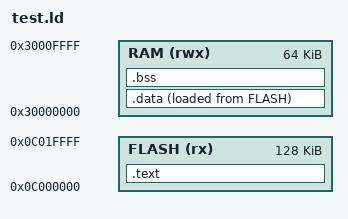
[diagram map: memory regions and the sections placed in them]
/* test.ld
 *
 * Copyright (C) 2026 wolfSSL Inc.
 *
 * This file is part of wolfTrust.
 *
 * wolfTrust is free software; you can redistribute it and/or modify
 * it under the terms of the GNU General Public License as published by
 * the Free Software Foundation; either version 3 of the License, or
 * (at your option) any later version.
 *
 * wolfTrust is distributed in the hope that it will be useful,
 * but WITHOUT ANY WARRANTY; without even the implied warranty of
 * MERCHANTABILITY or FITNESS FOR A PARTICULAR PURPOSE.  See the
 * GNU General Public License for more details.
 *
 * You should have received a copy of the GNU General Public License
 * along with this program; if not, see <https://www.gnu.org/licenses/>.
 */

ENTRY(Reset_Handler)
MEMORY
{
    FLASH (rx) : ORIGIN = 0x0C000000, LENGTH = 128K
    RAM (rwx) : ORIGIN = 0x30000000, LENGTH = 64K
}
_estack = ORIGIN(RAM) + LENGTH(RAM);
SECTIONS
{
    .text : {
        KEEP(*(.vectors))
        *(.text*)
        *(.rodata*)
    } > FLASH
    .data : { *(.data*) } > RAM AT > FLASH
    .bss (NOLOAD) : {
        _sbss = .;
        *(.bss*)
        *(COMMON)
        _ebss = .;
    } > RAM
}
